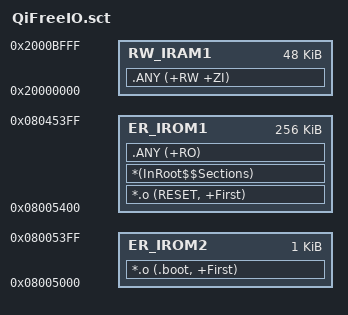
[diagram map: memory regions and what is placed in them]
; *************************************************************
; *** Scatter-Loading Description File generated by uVision ***
; *************************************************************

LR_IROM1 0x08005000 0x00040000  {    ; load region size_region
  ER_IROM2 0x08005000 0x00000400  {  ; load address = execution address
   *.o (.boot, +First)
  }
  ER_IROM1 0x08005400 0x00040000  {  ; load address = execution address
   *.o (RESET, +First)
   *(InRoot$$Sections)
   .ANY (+RO)
  }
  RW_IRAM1 0x20000000 0x0000C000  {  ; RW data
   .ANY (+RW +ZI)
  }
}

